AUTOSAR XML (schema 3.1.2)
package /Components/SWC_VSMax
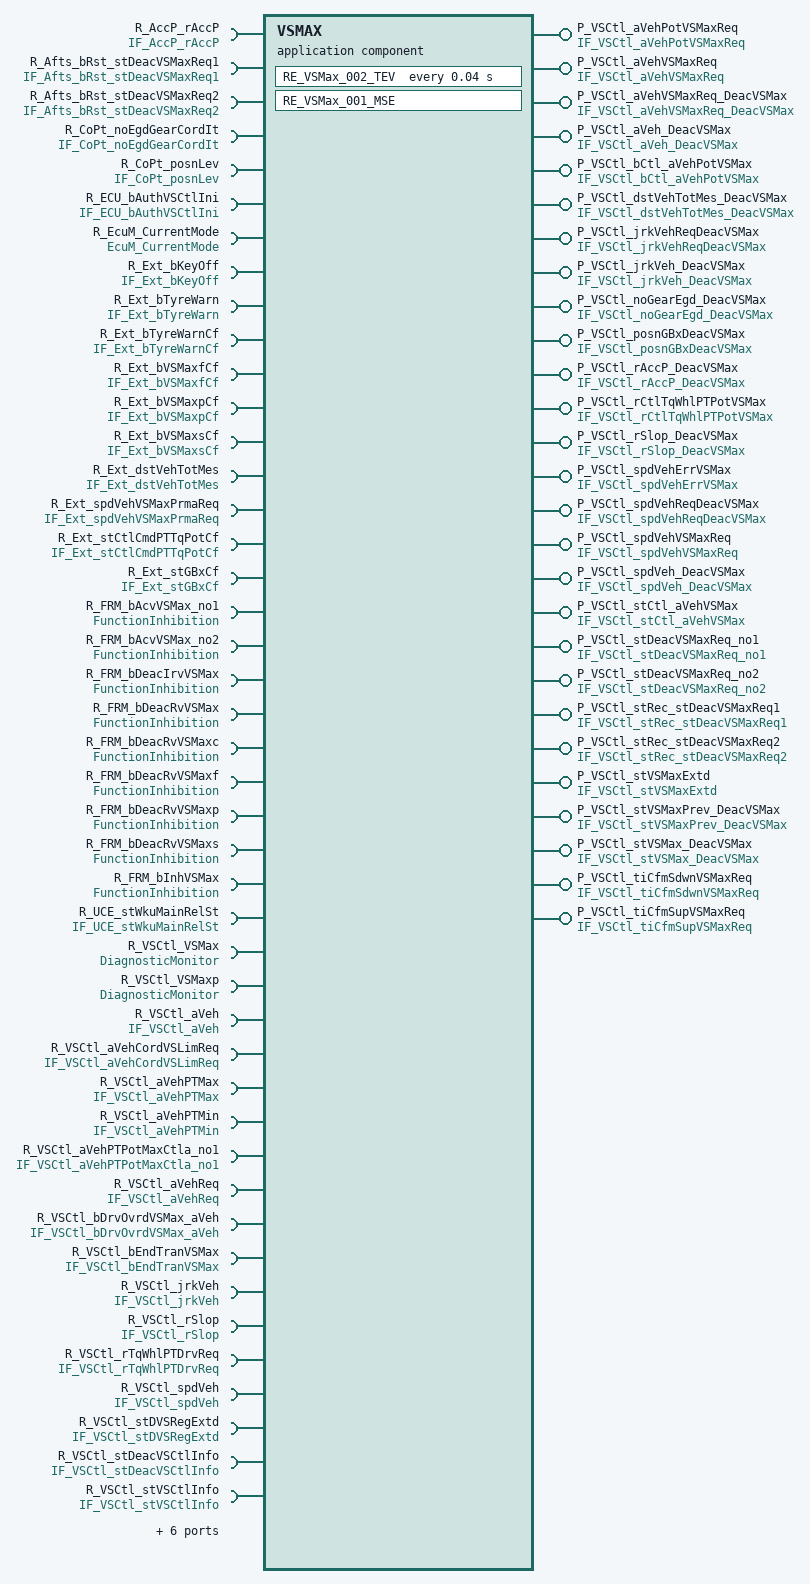
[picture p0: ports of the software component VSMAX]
  application software component type VSMAX  # VSMax
    27 x provide port:
      P_VSCtl_aVehPotVSMaxReq: unqueued-sender-com-spec{data-element=VSCtl_aVehPotVSMaxReq, can-invalidate=false, init-value=ConstantValue}, provided-interface=IF_VSCtl_aVehPotVSMaxReq
      P_VSCtl_aVehVSMaxReq: unqueued-sender-com-spec{data-element=VSCtl_aVehVSMaxReq, can-invalidate=false, init-value=ConstantValue1}, provided-interface=IF_VSCtl_aVehVSMaxReq
      P_VSCtl_aVehVSMaxReq_DeacVSMax: unqueued-sender-com-spec{data-element=VSCtl_aVehVSMaxReq_DeacVSMax, can-invalidate=false, init-value=C_SInt16_10240}, provided-interface=IF_VSCtl_aVehVSMaxReq_DeacVSMax
      P_VSCtl_aVeh_DeacVSMax: unqueued-sender-com-spec{data-element=VSCtl_aVeh_DeacVSMax, can-invalidate=false, init-value=C_SInt16_0}, provided-interface=IF_VSCtl_aVeh_DeacVSMax
      P_VSCtl_bCtl_aVehPotVSMax: unqueued-sender-com-spec{data-element=VSCtl_bCtl_aVehPotVSMax, can-invalidate=false, init-value=ConstantValue3}, provided-interface=IF_VSCtl_bCtl_aVehPotVSMax
      P_VSCtl_dstVehTotMes_DeacVSMax: unqueued-sender-com-spec{data-element=VSCtl_dstVehTotMes_DeacVSMax, can-invalidate=false, init-value=C_UInt32_0}, provided-interface=IF_VSCtl_dstVehTotMes_DeacVSMax
      P_VSCtl_jrkVehReqDeacVSMax: unqueued-sender-com-spec{data-element=VSCtl_jrkVehReqDeacVSMax, can-invalidate=false, init-value=C_SInt16_05}, provided-interface=IF_VSCtl_jrkVehReqDeacVSMax
      P_VSCtl_jrkVeh_DeacVSMax: unqueued-sender-com-spec{data-element=VSCtl_jrkVeh_DeacVSMax, can-invalidate=false, init-value=C_SInt16_07}, provided-interface=IF_VSCtl_jrkVeh_DeacVSMax
      P_VSCtl_noGearEgd_DeacVSMax: unqueued-sender-com-spec{data-element=VSCtl_noGearEgd_DeacVSMax, can-invalidate=false, init-value=C_SInt8_0}, provided-interface=IF_VSCtl_noGearEgd_DeacVSMax
      P_VSCtl_posnGBxDeacVSMax: unqueued-sender-com-spec{data-element=VSCtl_posnGBxDeacVSMax, can-invalidate=false, init-value=C_UInt8_0}, provided-interface=IF_VSCtl_posnGBxDeacVSMax
      P_VSCtl_rAccP_DeacVSMax: unqueued-sender-com-spec{data-element=VSCtl_rAccP_DeacVSMax, can-invalidate=false, init-value=C_UInt16_12800}, provided-interface=IF_VSCtl_rAccP_DeacVSMax
      P_VSCtl_rCtlTqWhlPTPotVSMax: unqueued-sender-com-spec{data-element=VSCtl_rCtlTqWhlPTPotVSMax, can-invalidate=false, init-value=ConstantValue9}, provided-interface=IF_VSCtl_rCtlTqWhlPTPotVSMax
      P_VSCtl_rSlop_DeacVSMax: unqueued-sender-com-spec{data-element=VSCtl_rSlop_DeacVSMax, can-invalidate=false, init-value=C_SInt16_011}, provided-interface=IF_VSCtl_rSlop_DeacVSMax
      P_VSCtl_spdVehErrVSMax: unqueued-sender-com-spec{data-element=VSCtl_spdVehErrVSMax, can-invalidate=false, init-value=C_SInt16_013}, provided-interface=IF_VSCtl_spdVehErrVSMax
      P_VSCtl_spdVehReqDeacVSMax: unqueued-sender-com-spec{data-element=VSCtl_spdVehReqDeacVSMax, can-invalidate=false, init-value=C_UInt16_0}, provided-interface=IF_VSCtl_spdVehReqDeacVSMax
      P_VSCtl_spdVehVSMaxReq: unqueued-sender-com-spec{data-element=VSCtl_spdVehVSMaxReq, can-invalidate=false, init-value=C_UInt16_32640}, provided-interface=IF_VSCtl_spdVehVSMaxReq
      P_VSCtl_spdVeh_DeacVSMax: unqueued-sender-com-spec{data-element=VSCtl_spdVeh_DeacVSMax, can-invalidate=false, init-value=C_UInt16_015}, provided-interface=IF_VSCtl_spdVeh_DeacVSMax
      P_VSCtl_stCtl_aVehVSMax: unqueued-sender-com-spec{data-element=VSCtl_stCtl_aVehVSMax, can-invalidate=false, init-value=ConstantValue17}, provided-interface=IF_VSCtl_stCtl_aVehVSMax
      P_VSCtl_stDeacVSMaxReq_no1: unqueued-sender-com-spec{data-element=VSCtl_stDeacVSMaxReq_no1, can-invalidate=false, init-value=C_UInt16_16383}, provided-interface=IF_VSCtl_stDeacVSMaxReq_no1
      P_VSCtl_stDeacVSMaxReq_no2: unqueued-sender-com-spec{data-element=VSCtl_stDeacVSMaxReq_no2, can-invalidate=false, init-value=C_UInt16_1638319}, provided-interface=IF_VSCtl_stDeacVSMaxReq_no2
      P_VSCtl_stRec_stDeacVSMaxReq1: unqueued-sender-com-spec{data-element=VSCtl_stRec_stDeacVSMaxReq1, can-invalidate=false, init-value=C_UInt8_021}, provided-interface=IF_VSCtl_stRec_stDeacVSMaxReq1
      P_VSCtl_stRec_stDeacVSMaxReq2: unqueued-sender-com-spec{data-element=VSCtl_stRec_stDeacVSMaxReq2, can-invalidate=false, init-value=C_UInt8_023}, provided-interface=IF_VSCtl_stRec_stDeacVSMaxReq2
      P_VSCtl_stVSMaxExtd: unqueued-sender-com-spec{data-element=VSCtl_stVSMaxExtd, can-invalidate=false, init-value=C_UInt8_025}, provided-interface=IF_VSCtl_stVSMaxExtd
      P_VSCtl_stVSMaxPrev_DeacVSMax: unqueued-sender-com-spec{data-element=VSCtl_stVSMaxPrev_DeacVSMax, can-invalidate=false, init-value=C_UInt8_027}, provided-interface=IF_VSCtl_stVSMaxPrev_DeacVSMax
      P_VSCtl_stVSMax_DeacVSMax: unqueued-sender-com-spec{data-element=VSCtl_stVSMax_DeacVSMax, can-invalidate=false, init-value=C_UInt8_029}, provided-interface=IF_VSCtl_stVSMax_DeacVSMax
      P_VSCtl_tiCfmSdwnVSMaxReq: unqueued-sender-com-spec{data-element=VSCtl_tiCfmSdwnVSMaxReq, can-invalidate=false, init-value=ConstantValue31}, provided-interface=IF_VSCtl_tiCfmSdwnVSMaxReq
      P_VSCtl_tiCfmSupVSMaxReq: unqueued-sender-com-spec{data-element=VSCtl_tiCfmSupVSMaxReq, can-invalidate=false, init-value=ConstantValue33}, provided-interface=IF_VSCtl_tiCfmSupVSMaxReq
    50 x require port:
      R_AccP_rAccP: unqueued-receiver-com-spec{data-element=AccP_rAccP, init-value=ConstantValue35, resync-time=0}, required-interface=IF_AccP_rAccP
      R_Afts_bRst_stDeacVSMaxReq1: unqueued-receiver-com-spec{data-element=Afts_bRst_stDeacVSMaxReq1, init-value=C_Boolean_False, resync-time=0}, required-interface=IF_Afts_bRst_stDeacVSMaxReq1
      R_Afts_bRst_stDeacVSMaxReq2: unqueued-receiver-com-spec{data-element=Afts_bRst_stDeacVSMaxReq2, init-value=C_Boolean_False37, resync-time=0}, required-interface=IF_Afts_bRst_stDeacVSMaxReq2
      R_CoPt_noEgdGearCordIt: unqueued-receiver-com-spec{data-element=CoPt_noEgdGearCordIt, init-value=ConstantValue39, resync-time=0}, required-interface=IF_CoPt_noEgdGearCordIt
      R_CoPt_posnLev: unqueued-receiver-com-spec{data-element=CoPt_posnLev, init-value=ConstantValue41, resync-time=0}, required-interface=IF_CoPt_posnLev
      R_ECU_bAuthVSCtlIni: unqueued-receiver-com-spec{data-element=ECU_bAuthVSCtlIni, init-value=ConstantValue43, resync-time=0}, required-interface=IF_ECU_bAuthVSCtlIni
      R_EcuM_CurrentMode: required-interface=EcuM_CurrentMode  # Requirement: 01552_09_00532-SSTG-C007(2)
      R_Ext_bKeyOff: unqueued-receiver-com-spec{data-element=Ext_bKeyOff, init-value=ConstantValue45, resync-time=0}, required-interface=IF_Ext_bKeyOff
      R_Ext_bTyreWarn: unqueued-receiver-com-spec{data-element=Ext_bTyreWarn, init-value=ConstantValue47, resync-time=0}, required-interface=IF_Ext_bTyreWarn
      R_Ext_bTyreWarnCf: unqueued-receiver-com-spec{data-element=Ext_bTyreWarnCf, init-value=ConstantValue49, resync-time=0}, required-interface=IF_Ext_bTyreWarnCf
      R_Ext_bVSMaxfCf: unqueued-receiver-com-spec{data-element=Ext_bVSMaxfCf, init-value=ConstantValue51, resync-time=0}, required-interface=IF_Ext_bVSMaxfCf
      R_Ext_bVSMaxpCf: unqueued-receiver-com-spec{data-element=Ext_bVSMaxpCf, init-value=ConstantValue53, resync-time=0}, required-interface=IF_Ext_bVSMaxpCf
      R_Ext_bVSMaxsCf: unqueued-receiver-com-spec{data-element=Ext_bVSMaxsCf, init-value=ConstantValue55, resync-time=0}, required-interface=IF_Ext_bVSMaxsCf
      R_Ext_dstVehTotMes: unqueued-receiver-com-spec{data-element=Ext_dstVehTotMes, init-value=ConstantValue57, resync-time=0}, required-interface=IF_Ext_dstVehTotMes
      R_Ext_spdVehVSMaxPrmaReq: unqueued-receiver-com-spec{data-element=Ext_spdVehVSMaxPrmaReq, init-value=C_UInt8_059, resync-time=0}, required-interface=IF_Ext_spdVehVSMaxPrmaReq
      R_Ext_stCtlCmdPTTqPotCf: unqueued-receiver-com-spec{data-element=Ext_stCtlCmdPTTqPotCf, init-value=ConstantValue61, resync-time=0}, required-interface=IF_Ext_stCtlCmdPTTqPotCf
      R_Ext_stGBxCf: unqueued-receiver-com-spec{data-element=Ext_stGBxCf, init-value=ConstantValue63, resync-time=0}, required-interface=IF_Ext_stGBxCf
      R_FRM_bAcvVSMax_no1: required-interface=FunctionInhibition
      R_FRM_bAcvVSMax_no2: required-interface=FunctionInhibition
      R_FRM_bDeacIrvVSMax: required-interface=FunctionInhibition
      R_FRM_bDeacRvVSMax: required-interface=FunctionInhibition
      R_FRM_bDeacRvVSMaxc: required-interface=FunctionInhibition
      R_FRM_bDeacRvVSMaxf: required-interface=FunctionInhibition
      R_FRM_bDeacRvVSMaxp: required-interface=FunctionInhibition
      R_FRM_bDeacRvVSMaxs: required-interface=FunctionInhibition
      R_FRM_bInhVSMax: required-interface=FunctionInhibition
      R_UCE_stWkuMainRelSt: required-interface=IF_UCE_stWkuMainRelSt  # Requirement: 01552_09_00532-SSTG-C011(1)
      R_VSCtl_VSMax: required-interface=DiagnosticMonitor
      R_VSCtl_VSMaxp: required-interface=DiagnosticMonitor
      R_VSCtl_aVeh: unqueued-receiver-com-spec{data-element=VSCtl_aVeh, init-value=ConstantValue65, resync-time=0}, required-interface=IF_VSCtl_aVeh
      R_VSCtl_aVehCordVSLimReq: unqueued-receiver-com-spec{data-element=VSCtl_aVehCordVSLimReq, init-value=ConstantValue67, resync-time=0}, required-interface=IF_VSCtl_aVehCordVSLimReq
      R_VSCtl_aVehPTMax: unqueued-receiver-com-spec{data-element=VSCtl_aVehPTMax, init-value=ConstantValue69, resync-time=0}, required-interface=IF_VSCtl_aVehPTMax
      R_VSCtl_aVehPTMin: unqueued-receiver-com-spec{data-element=VSCtl_aVehPTMin, init-value=ConstantValue71, resync-time=0}, required-interface=IF_VSCtl_aVehPTMin
      R_VSCtl_aVehPTPotMaxCtla_no1: unqueued-receiver-com-spec{data-element=VSCtl_aVehPTPotMaxCtla_no1, init-value=ConstantValue73, resync-time=0}, required-interface=IF_VSCtl_aVehPTPotMaxCtla_no1
      R_VSCtl_aVehReq: unqueued-receiver-com-spec{data-element=VSCtl_aVehReq, init-value=ConstantValue75, resync-time=0}, required-interface=IF_VSCtl_aVehReq
      R_VSCtl_bDrvOvrdVSMax_aVeh: unqueued-receiver-com-spec{data-element=VSCtl_bDrvOvrdVSMax_aVeh, init-value=ConstantValue77, resync-time=0}, required-interface=IF_VSCtl_bDrvOvrdVSMax_aVeh
      R_VSCtl_bEndTranVSMax: unqueued-receiver-com-spec{data-element=VSCtl_bEndTranVSMax, init-value=ConstantValue79, resync-time=0}, required-interface=IF_VSCtl_bEndTranVSMax
      R_VSCtl_jrkVeh: unqueued-receiver-com-spec{data-element=VSCtl_jrkVeh, init-value=ConstantValue81, resync-time=0}, required-interface=IF_VSCtl_jrkVeh
      R_VSCtl_rSlop: unqueued-receiver-com-spec{data-element=VSCtl_rSlop, init-value=ConstantValue83, resync-time=0}, required-interface=IF_VSCtl_rSlop
      R_VSCtl_rTqWhlPTDrvReq: unqueued-receiver-com-spec{data-element=VSCtl_rTqWhlPTDrvReq, init-value=ConstantValue85, resync-time=0}, required-interface=IF_VSCtl_rTqWhlPTDrvReq
      R_VSCtl_spdVeh: unqueued-receiver-com-spec{data-element=VSCtl_spdVeh, init-value=ConstantValue87, resync-time=0}, required-interface=IF_VSCtl_spdVeh
      R_VSCtl_stDVSRegExtd: unqueued-receiver-com-spec{data-element=VSCtl_stDVSRegExtd, init-value=C_UInt8_089, resync-time=0}, required-interface=IF_VSCtl_stDVSRegExtd
      R_VSCtl_stDeacVSCtlInfo: unqueued-receiver-com-spec{data-element=VSCtl_stDeacVSCtlInfo, init-value=ConstantValue91, resync-time=0}, required-interface=IF_VSCtl_stDeacVSCtlInfo
      R_VSCtl_stVSCtlInfo: unqueued-receiver-com-spec{data-element=VSCtl_stVSCtlInfo, init-value=ConstantValue93, resync-time=0}, required-interface=IF_VSCtl_stVSCtlInfo
      R_VSCtl_stVSLimExtd: unqueued-receiver-com-spec{data-element=VSCtl_stVSLimExtd, init-value=ConstantValue95, resync-time=0}, required-interface=IF_VSCtl_stVSLimExtd
      R_VSCtl_stVSRegExtd: unqueued-receiver-com-spec{data-element=VSCtl_stVSRegExtd, init-value=C_UInt8_097, resync-time=0}, required-interface=IF_VSCtl_stVSRegExtd
      R_VSMax_GetTimer_1ms_U32: required-interface=IF_CS_FRunTime_1MS_U32
      R_VehEst_spdVehCrit: unqueued-receiver-com-spec{data-element=VehEst_spdVehCrit, init-value=C_UInt8_099, resync-time=0}, required-interface=IF_VehEst_spdVehCrit
      R_Veh_spdVeh: unqueued-receiver-com-spec{data-element=Veh_spdVeh, init-value=ConstantValue101, resync-time=0}, required-interface=IF_Veh_spdVeh
      R_Ext_bCtlCmdPTTqCf: unqueued-receiver-com-spec{data-element=Ext_bCtlCmdPTTqCf, init-value=ConstantValue103, resync-time=0}, required-interface=IF_Ext_bCtlCmdPTTqCf  # R_Ext_bVSMaxpCf
  63 x constant specification:
    C_Boolean_False
      value:
        boolean literal C_Boolean_False: type=DT_Afts_bRst_stDeacVSMaxReq1, value=false
    C_Boolean_False37
      value:
        boolean literal C_Boolean_False37: type=DT_Afts_bRst_stDeacVSMaxReq2, value=false
    C_SInt16_0
      value:
        integer literal C_SInt16_0: type=DT_VSCtl_aVeh_DeacVSMax, value=0
    C_SInt16_011
      value:
        integer literal C_SInt16_011: type=DT_VSCtl_rSlop_DeacVSMax, value=0
    C_SInt16_013
      value:
        integer literal C_SInt16_013: type=DT_VSCtl_spdVehErrVSMax, value=0
    C_SInt16_05
      value:
        integer literal C_SInt16_05: type=DT_VSCtl_jrkVehReqDeacVSMax, value=0
    C_SInt16_07
      value:
        integer literal C_SInt16_07: type=DT_VSCtl_jrkVeh_DeacVSMax, value=0
    C_SInt16_10240
      value:
        integer literal C_SInt16_10240: type=DT_VSCtl_aVehVSMaxReq_DeacVSMax, value=10240
    C_SInt8_0
      value:
        integer literal C_SInt8_0: type=DT_VSCtl_noGearEgd_DeacVSMax, value=0
    C_UInt16_0
      value:
        integer literal C_UInt16_0: type=DT_VSCtl_spdVehReqDeacVSMax, value=0
    C_UInt16_015
      value:
        integer literal C_UInt16_015: type=DT_VSCtl_spdVeh_DeacVSMax, value=0
    C_UInt16_12800
      value:
        integer literal C_UInt16_12800: type=DT_VSCtl_rAccP_DeacVSMax, value=12800
    C_UInt16_16383
      value:
        integer literal C_UInt16_16383: type=DT_VSCtl_stDeacVSMaxReq_no1, value=16383
    C_UInt16_1638319
      value:
        integer literal C_UInt16_1638319: type=DT_VSCtl_stDeacVSMaxReq_no2, value=16383
    C_UInt16_32640
      value:
        integer literal C_UInt16_32640: type=DT_VSCtl_spdVehVSMaxReq, value=32640
    C_UInt32_0
      value:
        integer literal C_UInt32_0: type=DT_VSCtl_dstVehTotMes_DeacVSMax, value=0
    C_UInt8_0
      value:
        integer literal C_UInt8_0: type=DT_VSCtl_posnGBxDeacVSMax, value=0
    C_UInt8_021
      value:
        integer literal C_UInt8_021: type=DT_VSCtl_stRec_stDeacVSMaxReq1, value=0
    C_UInt8_023
      value:
        integer literal C_UInt8_023: type=DT_VSCtl_stRec_stDeacVSMaxReq2, value=0
    C_UInt8_025
      value:
        integer literal C_UInt8_025: type=DT_VSCtl_stVSMaxExtd, value=0
    C_UInt8_027
      value:
        integer literal C_UInt8_027: type=DT_VSCtl_stVSMaxPrev_DeacVSMax, value=0
    C_UInt8_029
      value:
        integer literal C_UInt8_029: type=DT_VSCtl_stVSMax_DeacVSMax, value=0
    C_UInt8_059
      value:
        integer literal C_UInt8_059: type=DT_Ext_spdVehVSMaxPrmaReq, value=255
    C_UInt8_089
      value:
        integer literal C_UInt8_089: type=DT_VSCtl_stDVSRegExtd, value=0
    C_UInt8_097
      value:
        integer literal C_UInt8_097: type=DT_VSCtl_stVSRegExtd, value=0
    C_UInt8_099
      value:
        integer literal C_UInt8_099: type=DT_VehEst_spdVehCrit, value=255
    ConstantValue
      value:
        integer literal ConstantValue: type=DT_VSCtl_aVehPotVSMaxReq, value=0
    ConstantValue1
      value:
        integer literal ConstantValue1: type=DT_VSCtl_aVehVSMaxReq, value=0
    ConstantValue101
      value:
        integer literal ConstantValue101: type=DT_Veh_spdVeh, value=0
    ConstantValue103
      value:
        boolean literal ConstantValue103: type=DT_Ext_bCtlCmdPTTqCf, value=false
    ConstantValue17
      value:
        integer literal ConstantValue17: type=DT_VSCtl_stCtl_aVehVSMax, value=0
    ConstantValue3
      value:
        integer literal ConstantValue3: type=DT_VSCtl_bCtl_aVehPotVSMax, value=0
    ConstantValue31
      value:
        integer literal ConstantValue31: type=DT_VSCtl_tiCfmSdwnVSMaxReq, value=0
    ConstantValue33
      value:
        integer literal ConstantValue33: type=DT_VSCtl_tiCfmSupVSMaxReq, value=0
    ConstantValue35
      value:
        integer literal ConstantValue35: type=DT_AccP_rAccP, value=0
    ConstantValue39
      value:
        integer literal ConstantValue39: type=DT_CoPt_noEgdGearCordIt, value=0
    ConstantValue41
      value:
        integer literal ConstantValue41: type=DT_CoPt_posnLev, value=0
    ConstantValue43
      value:
        boolean literal ConstantValue43: type=DT_ECU_bAuthVSCtlIni, value=false
    ConstantValue45
      value:
        boolean literal ConstantValue45: type=DT_Ext_bKeyOff, value=false
    ConstantValue47
      value:
        boolean literal ConstantValue47: type=DT_Ext_bTyreWarn, value=false
    ConstantValue49
      value:
        boolean literal ConstantValue49: type=DT_Ext_bTyreWarnCf, value=false
    ConstantValue51
      value:
        boolean literal ConstantValue51: type=DT_Ext_bVSMaxfCf, value=false
    ConstantValue53
      value:
        boolean literal ConstantValue53: type=DT_Ext_bVSMaxpCf, value=false
    ConstantValue55
      value:
        boolean literal ConstantValue55: type=DT_Ext_bVSMaxsCf, value=false
    ConstantValue57
      value:
        integer literal ConstantValue57: type=DT_Ext_dstVehTotMes, value=0
    ConstantValue61
      value:
        integer literal ConstantValue61: type=DT_Ext_stCtlCmdPTTqPotCf, value=0
    ConstantValue63
      value:
        integer literal ConstantValue63: type=DT_Ext_stGBxCf, value=0
    ConstantValue65
      value:
        integer literal ConstantValue65: type=DT_VSCtl_aVeh, value=0
    ConstantValue67
      value:
        integer literal ConstantValue67: type=DT_VSCtl_aVehCordVSLimReq, value=10240
    ConstantValue69
      value:
        integer literal ConstantValue69: type=DT_VSCtl_aVehPTMax, value=0
    ConstantValue71
      value:
        integer literal ConstantValue71: type=DT_VSCtl_aVehPTMin, value=0
    ConstantValue73
      value:
        integer literal ConstantValue73: type=DT_VSCtl_aVehPTPotMaxCtla_no1, value=10240
    ConstantValue75
      value:
        integer literal ConstantValue75: type=DT_VSCtl_aVehReq, value=-10240
    ConstantValue77
      value:
        boolean literal ConstantValue77: type=DT_VSCtl_bDrvOvrdVSMax_aVeh, value=true
    ConstantValue79
      value:
        boolean literal ConstantValue79: type=DT_VSCtl_bEndTranVSMax, value=true
    ConstantValue81
      value:
        integer literal ConstantValue81: type=DT_VSCtl_jrkVeh, value=0
    ConstantValue83
      value:
        integer literal ConstantValue83: type=DT_VSCtl_rSlop, value=0
    ConstantValue85
      value:
        integer literal ConstantValue85: type=DT_VSCtl_rTqWhlPTDrvReq, value=0
    ConstantValue87
      value:
        integer literal ConstantValue87: type=DT_VSCtl_spdVeh, value=0
    ConstantValue9
      value:
        integer literal ConstantValue9: type=DT_VSCtl_rCtlTqWhlPTPotVSMax, value=0
    ConstantValue91
      value:
        integer literal ConstantValue91: type=DT_VSCtl_stDeacVSCtlInfo, value=32
    ConstantValue93
      value:
        integer literal ConstantValue93: type=DT_VSCtl_stVSCtlInfo, value=0
    ConstantValue95
      value:
        integer literal ConstantValue95: type=DT_VSCtl_stVSLimExtd, value=0
  internal behavior IB_VSMax: component=VSMAX
    mode switch event EV_VSMax_001_MSE: start-on-event=RE_VSMax_001_MSE, activation=ENTRY, mode=R_EcuM_CurrentMode.currentMode.RUN
    timing event EV_VSMax_002_TEV: mode-dependency=dependent-on-mode=[R_UCE_stWkuMainRelSt.RCD_stWkuMainRelSt.Invalid, R_UCE_stWkuMainRelSt.RCD_stWkuMainRelSt.PostMainWakeUp, R_UCE_stWkuMainRelSt.RCD_stWkuMainRelSt.PreMainWakeUp], start-on-event=RE_VSMax_002_TEV, period=0.04
    runnable RE_VSMax_002_TEV  # RE_01552_10_02849_40ms
      36 x data receive point:
        dr_VSCtl_stDeacVSCtlInfo: data-element=R_VSCtl_stDeacVSCtlInfo.VSCtl_stDeacVSCtlInfo
        dr_VSCtl_stVSCtlInfo: data-element=R_VSCtl_stVSCtlInfo.VSCtl_stVSCtlInfo
        dr_VSCtl_stVSRegExtd: data-element=R_VSCtl_stVSRegExtd.VSCtl_stVSRegExtd
        dr_Ext_bVSMaxfCf: data-element=R_Ext_bVSMaxfCf.Ext_bVSMaxfCf
        dr_Afts_bRst_stDeacVSMaxReq2: data-element=R_Afts_bRst_stDeacVSMaxReq2.Afts_bRst_stDeacVSMaxReq2
        dr_VSCtl_aVehPTPotMaxCtla_no1: data-element=R_VSCtl_aVehPTPotMaxCtla_no1.VSCtl_aVehPTPotMaxCtla_no1
        dr_Ext_spdVehVSMaxPrmaReq: data-element=R_Ext_spdVehVSMaxPrmaReq.Ext_spdVehVSMaxPrmaReq
        dr_VSCtl_aVehPTMax: data-element=R_VSCtl_aVehPTMax.VSCtl_aVehPTMax
        dr_CoPt_noEgdGearCordIt: data-element=R_CoPt_noEgdGearCordIt.CoPt_noEgdGearCordIt
        dr_Ext_stGBxCf: data-element=R_Ext_stGBxCf.Ext_stGBxCf
        dr_Ext_bVSMaxsCf: data-element=R_Ext_bVSMaxsCf.Ext_bVSMaxsCf
        dr_Veh_spdVeh: data-element=R_Veh_spdVeh.Veh_spdVeh
        dr_VSCtl_aVehReq: data-element=R_VSCtl_aVehReq.VSCtl_aVehReq
        dr_VehEst_spdVehCrit: data-element=R_VehEst_spdVehCrit.VehEst_spdVehCrit
        dr_Ext_bTyreWarnCf: data-element=R_Ext_bTyreWarnCf.Ext_bTyreWarnCf
        dr_VSCtl_spdVeh: data-element=R_VSCtl_spdVeh.VSCtl_spdVeh
        dr_Ext_bKeyOff: data-element=R_Ext_bKeyOff.Ext_bKeyOff
        dr_VSCtl_bDrvOvrdVSMax_aVeh: data-element=R_VSCtl_bDrvOvrdVSMax_aVeh.VSCtl_bDrvOvrdVSMax_aVeh
        dr_VSCtl_bEndTranVSMax: data-element=R_VSCtl_bEndTranVSMax.VSCtl_bEndTranVSMax
        dr_AccP_rAccP: data-element=R_AccP_rAccP.AccP_rAccP
        dr_VSCtl_aVehCordVSLimReq: data-element=R_VSCtl_aVehCordVSLimReq.VSCtl_aVehCordVSLimReq
        dr_Ext_bVSMaxpCf: data-element=R_Ext_bVSMaxpCf.Ext_bVSMaxpCf
        dr_VSCtl_aVehPTMin: data-element=R_VSCtl_aVehPTMin.VSCtl_aVehPTMin
        dr_Afts_bRst_stDeacVSMaxReq1: data-element=R_Afts_bRst_stDeacVSMaxReq1.Afts_bRst_stDeacVSMaxReq1
        dr_VSCtl_aVeh: data-element=R_VSCtl_aVeh.VSCtl_aVeh
        dr_ECU_bAuthVSCtlIni: data-element=R_ECU_bAuthVSCtlIni.ECU_bAuthVSCtlIni
        dr_CoPt_posnLev: data-element=R_CoPt_posnLev.CoPt_posnLev
        dr_VSCtl_stDVSRegExtd: data-element=R_VSCtl_stDVSRegExtd.VSCtl_stDVSRegExtd
        DRP_R_Ext_bCtlCmdPTTqCf_Ext_bCtlCmdPTTqCf: data-element=R_Ext_bCtlCmdPTTqCf.Ext_bCtlCmdPTTqCf
        dr_Ext_bTyreWarn: data-element=R_Ext_bTyreWarn.Ext_bTyreWarn
        dr_Ext_dstVehTotMes: data-element=R_Ext_dstVehTotMes.Ext_dstVehTotMes
        dr_VSCtl_stVSLimExtd: data-element=R_VSCtl_stVSLimExtd.VSCtl_stVSLimExtd
        dr_VSCtl_jrkVeh: data-element=R_VSCtl_jrkVeh.VSCtl_jrkVeh
        dr_VSCtl_rSlop: data-element=R_VSCtl_rSlop.VSCtl_rSlop
        dr_VSCtl_rTqWhlPTDrvReq: data-element=R_VSCtl_rTqWhlPTDrvReq.VSCtl_rTqWhlPTDrvReq
        dr_Ext_stCtlCmdPTTqPotCf: data-element=R_Ext_stCtlCmdPTTqPotCf.Ext_stCtlCmdPTTqPotCf
      27 x data send point:
        ds_VSCtl_noGearEgd_DeacVSMax: data-element=P_VSCtl_noGearEgd_DeacVSMax.VSCtl_noGearEgd_DeacVSMax
        ds_VSCtl_jrkVeh_DeacVSMax: data-element=P_VSCtl_jrkVeh_DeacVSMax.VSCtl_jrkVeh_DeacVSMax
        ds_VSCtl_dstVehTotMes_DeacVSMax: data-element=P_VSCtl_dstVehTotMes_DeacVSMax.VSCtl_dstVehTotMes_DeacVSMax
        ds_VSCtl_spdVehReqDeacVSMax: data-element=P_VSCtl_spdVehReqDeacVSMax.VSCtl_spdVehReqDeacVSMax
        ds_VSCtl_aVehVSMaxReq: data-element=P_VSCtl_aVehVSMaxReq.VSCtl_aVehVSMaxReq
        ds_VSCtl_tiCfmSdwnVSMaxReq: data-element=P_VSCtl_tiCfmSdwnVSMaxReq.VSCtl_tiCfmSdwnVSMaxReq
        ds_VSCtl_stVSMaxPrev_DeacVSMax: data-element=P_VSCtl_stVSMaxPrev_DeacVSMax.VSCtl_stVSMaxPrev_DeacVSMax
        ds_VSCtl_stRec_stDeacVSMaxReq1: data-element=P_VSCtl_stRec_stDeacVSMaxReq1.VSCtl_stRec_stDeacVSMaxReq1
        ds_VSCtl_stRec_stDeacVSMaxReq2: data-element=P_VSCtl_stRec_stDeacVSMaxReq2.VSCtl_stRec_stDeacVSMaxReq2
        ds_VSCtl_spdVehErrVSMax: data-element=P_VSCtl_spdVehErrVSMax.VSCtl_spdVehErrVSMax
        ds_VSCtl_stVSMax_DeacVSMax: data-element=P_VSCtl_stVSMax_DeacVSMax.VSCtl_stVSMax_DeacVSMax
        ds_VSCtl_aVehVSMaxReq_DeacVSMax: data-element=P_VSCtl_aVehVSMaxReq_DeacVSMax.VSCtl_aVehVSMaxReq_DeacVSMax
        ds_VSCtl_posnGBxDeacVSMax: data-element=P_VSCtl_posnGBxDeacVSMax.VSCtl_posnGBxDeacVSMax
        ds_VSCtl_stDeacVSMaxReq_no2: data-element=P_VSCtl_stDeacVSMaxReq_no2.VSCtl_stDeacVSMaxReq_no2
        ds_VSCtl_rCtlTqWhlPTPotVSMax: data-element=P_VSCtl_rCtlTqWhlPTPotVSMax.VSCtl_rCtlTqWhlPTPotVSMax
        ds_VSCtl_aVehPotVSMaxReq: data-element=P_VSCtl_aVehPotVSMaxReq.VSCtl_aVehPotVSMaxReq
        ds_VSCtl_rAccP_DeacVSMax: data-element=P_VSCtl_rAccP_DeacVSMax.VSCtl_rAccP_DeacVSMax
        ds_VSCtl_spdVeh_DeacVSMax: data-element=P_VSCtl_spdVeh_DeacVSMax.VSCtl_spdVeh_DeacVSMax
        ds_VSCtl_spdVehVSMaxReq: data-element=P_VSCtl_spdVehVSMaxReq.VSCtl_spdVehVSMaxReq
        ds_VSCtl_stCtl_aVehVSMax: data-element=P_VSCtl_stCtl_aVehVSMax.VSCtl_stCtl_aVehVSMax
        ds_VSCtl_bCtl_aVehPotVSMax: data-element=P_VSCtl_bCtl_aVehPotVSMax.VSCtl_bCtl_aVehPotVSMax
        ds_VSCtl_aVeh_DeacVSMax: data-element=P_VSCtl_aVeh_DeacVSMax.VSCtl_aVeh_DeacVSMax
        ds_VSCtl_tiCfmSupVSMaxReq: data-element=P_VSCtl_tiCfmSupVSMaxReq.VSCtl_tiCfmSupVSMaxReq
        ds_VSCtl_stVSMaxExtd: data-element=P_VSCtl_stVSMaxExtd.VSCtl_stVSMaxExtd
        ds_VSCtl_stDeacVSMaxReq_no1: data-element=P_VSCtl_stDeacVSMaxReq_no1.VSCtl_stDeacVSMaxReq_no1
        ds_VSCtl_rSlop_DeacVSMax: data-element=P_VSCtl_rSlop_DeacVSMax.VSCtl_rSlop_DeacVSMax
        ds_VSCtl_jrkVehReqDeacVSMax: data-element=P_VSCtl_jrkVehReqDeacVSMax.VSCtl_jrkVehReqDeacVSMax
      12 x sync call:
        ssp_FRM_bAcvVSMax_no1: operation=R_FRM_bAcvVSMax_no1.GetFunctionPermission
        ssp_FRM_bDeacIrvVSMax: operation=R_FRM_bDeacIrvVSMax.GetFunctionPermission
        ssp_FRM_bDeacRvVSMaxc: operation=R_FRM_bDeacRvVSMaxc.GetFunctionPermission
        ssp_FRM_bDeacRvVSMaxp: operation=R_FRM_bDeacRvVSMaxp.GetFunctionPermission
        ssp_FRM_bInhVSMax: operation=R_FRM_bInhVSMax.GetFunctionPermission
        ssp_VSCtl_VSMaxp: operation=R_VSCtl_VSMaxp.SetEventStatus
        ssp_GetTimer_1ms_U32: operation=R_VSMax_GetTimer_1ms_U32.GetTimer_1ms_U32
        ssp_FRM_bDeacRvVSMaxs: operation=R_FRM_bDeacRvVSMaxs.GetFunctionPermission
        ssp_FRM_bDeacRvVSMax: operation=R_FRM_bDeacRvVSMax.GetFunctionPermission
        ssp_FRM_bDeacRvVSMaxf: operation=R_FRM_bDeacRvVSMaxf.GetFunctionPermission
        ssp_FRM_bAcvVSMax_no2: operation=R_FRM_bAcvVSMax_no2.GetFunctionPermission
        ssp_VSCtl_VSMax: operation=R_VSCtl_VSMax.SetEventStatus
    runnable RE_VSMax_001_MSE  # RE_01552_10_02849_10ms_init
      27 x data send point:
        ds_VSCtl_noGearEgd_DeacVSMax: data-element=P_VSCtl_noGearEgd_DeacVSMax.VSCtl_noGearEgd_DeacVSMax
        ds_VSCtl_tiCfmSdwnVSMaxReq: data-element=P_VSCtl_tiCfmSdwnVSMaxReq.VSCtl_tiCfmSdwnVSMaxReq
        ds_VSCtl_spdVehVSMaxReq: data-element=P_VSCtl_spdVehVSMaxReq.VSCtl_spdVehVSMaxReq
        ds_VSCtl_tiCfmSupVSMaxReq: data-element=P_VSCtl_tiCfmSupVSMaxReq.VSCtl_tiCfmSupVSMaxReq
        ds_VSCtl_posnGBxDeacVSMax: data-element=P_VSCtl_posnGBxDeacVSMax.VSCtl_posnGBxDeacVSMax
        ds_VSCtl_stVSMaxPrev_DeacVSMax: data-element=P_VSCtl_stVSMaxPrev_DeacVSMax.VSCtl_stVSMaxPrev_DeacVSMax
        ds_VSCtl_jrkVeh_DeacVSMax: data-element=P_VSCtl_jrkVeh_DeacVSMax.VSCtl_jrkVeh_DeacVSMax
        ds_VSCtl_stRec_stDeacVSMaxReq1: data-element=P_VSCtl_stRec_stDeacVSMaxReq1.VSCtl_stRec_stDeacVSMaxReq1
        ds_VSCtl_spdVehErrVSMax: data-element=P_VSCtl_spdVehErrVSMax.VSCtl_spdVehErrVSMax
        ds_VSCtl_stVSMax_DeacVSMax: data-element=P_VSCtl_stVSMax_DeacVSMax.VSCtl_stVSMax_DeacVSMax
        ds_VSCtl_spdVeh_DeacVSMax: data-element=P_VSCtl_spdVeh_DeacVSMax.VSCtl_spdVeh_DeacVSMax
        ds_VSCtl_aVehPotVSMaxReq: data-element=P_VSCtl_aVehPotVSMaxReq.VSCtl_aVehPotVSMaxReq
        ds_VSCtl_jrkVehReqDeacVSMax: data-element=P_VSCtl_jrkVehReqDeacVSMax.VSCtl_jrkVehReqDeacVSMax
        ds_VSCtl_aVeh_DeacVSMax: data-element=P_VSCtl_aVeh_DeacVSMax.VSCtl_aVeh_DeacVSMax
        ds_VSCtl_rCtlTqWhlPTPotVSMax: data-element=P_VSCtl_rCtlTqWhlPTPotVSMax.VSCtl_rCtlTqWhlPTPotVSMax
        ds_VSCtl_rAccP_DeacVSMax: data-element=P_VSCtl_rAccP_DeacVSMax.VSCtl_rAccP_DeacVSMax
        ds_VSCtl_stDeacVSMaxReq_no1: data-element=P_VSCtl_stDeacVSMaxReq_no1.VSCtl_stDeacVSMaxReq_no1
        ds_VSCtl_stRec_stDeacVSMaxReq2: data-element=P_VSCtl_stRec_stDeacVSMaxReq2.VSCtl_stRec_stDeacVSMaxReq2
        ds_VSCtl_stVSMaxExtd: data-element=P_VSCtl_stVSMaxExtd.VSCtl_stVSMaxExtd
        ds_VSCtl_stDeacVSMaxReq_no2: data-element=P_VSCtl_stDeacVSMaxReq_no2.VSCtl_stDeacVSMaxReq_no2
        ds_VSCtl_aVehVSMaxReq: data-element=P_VSCtl_aVehVSMaxReq.VSCtl_aVehVSMaxReq
        ds_VSCtl_aVehVSMaxReq_DeacVSMax: data-element=P_VSCtl_aVehVSMaxReq_DeacVSMax.VSCtl_aVehVSMaxReq_DeacVSMax
        ds_VSCtl_spdVehReqDeacVSMax: data-element=P_VSCtl_spdVehReqDeacVSMax.VSCtl_spdVehReqDeacVSMax
        ds_VSCtl_dstVehTotMes_DeacVSMax: data-element=P_VSCtl_dstVehTotMes_DeacVSMax.VSCtl_dstVehTotMes_DeacVSMax
        ds_VSCtl_bCtl_aVehPotVSMax: data-element=P_VSCtl_bCtl_aVehPotVSMax.VSCtl_bCtl_aVehPotVSMax
        ds_VSCtl_rSlop_DeacVSMax: data-element=P_VSCtl_rSlop_DeacVSMax.VSCtl_rSlop_DeacVSMax
        ds_VSCtl_stCtl_aVehVSMax: data-element=P_VSCtl_stCtl_aVehVSMax.VSCtl_stCtl_aVehVSMax
      sync call ssp_GetTimer_1ms_U32: operation=R_VSMax_GetTimer_1ms_U32.GetTimer_1ms_U32
  swc implementation Imp_VSMax: programming-language=C, behavior=IB_VSMax
    code-descriptors:
      code CodeDescriptor: type=SRC
        7 x xfile:
          VSMAX_Fct_Mode_Sl_c: url=VSMAX_Fct_Mode_Sl.c
          VSMAX_Veh_Acc_Ctrl_Sl_c: url=VSMAX_Veh_Acc_Ctrl_Sl.c
          VSMax_c: url=VSMax.c
          VSMAX_Veh_Spd_Ctrl_Sl_c: url=VSMAX_Veh_Spd_Ctrl_Sl.c
          VSMAX_Re002tev_Sf_c: url=VSMAX_Re002tev_Sf.c
          VSMax_h: url=VSMax.h
          VSMax_MemMap_h: url=VSMax_MemMap.h
